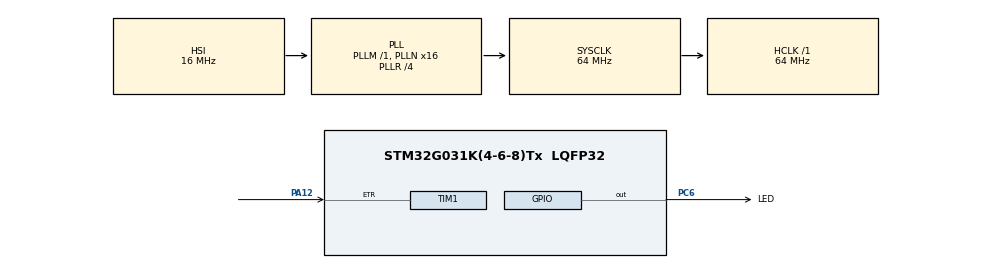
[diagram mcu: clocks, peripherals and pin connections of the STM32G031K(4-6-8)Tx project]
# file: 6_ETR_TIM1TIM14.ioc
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Mcu.Family=STM32G0
Mcu.Name=STM32G031K(4-6-8)Tx
Mcu.Package=LQFP32
NVIC.TIM17_IRQn=true\:0\:0\:false\:false\:true\:true\:true\:true
PA12\ [PA10].Signal=S_TIM1_ETR
PC6.GPIO_Label=LED
PC6.Signal=GPIO_Output
ProjectManager.HeapSize=0x200
ProjectManager.StackSize=0x400
ProjectManager.TargetToolchain=STM32CubeIDE
RCC.ADCFreq_Value=64000000
RCC.AHBFreq_Value=64000000
RCC.CortexFreq_Value=64000000
RCC.EXTERNAL_CLOCK_VALUE=12288000
RCC.HCLKFreq_Value=64000000
RCC.HSE_VALUE=8000000
RCC.HSI_VALUE=16000000
RCC.LSE_VALUE=32768
RCC.PLLN=16
RCC.PLLR=RCC_PLLR_DIV4
RCC.SYSCLKFreq_VALUE=64000000
RCC.SYSCLKSource=RCC_SYSCLKSOURCE_PLLCLK
RCC.TIM1CLockSelectionVirtual=RCC_TIM1CLKSOURCE_PLL
RCC.VCOOutputFreq_Value=256000000
SH.S_TIM1_ETR.0=TIM1_ETR,ClockSourceETR_Mode2
TIM1.ClockPrescaler=TIM_CLOCKPRESCALER_DIV8
TIM1.Prescaler=0
TIM1.TIM_MasterOutputTrigger=TIM_TRGO_RESET
TIM1.TIM_MasterSlaveMode=TIM_MASTERSLAVEMODE_DISABLE
TIM17.Channel=TIM_CHANNEL_1
TIM17.OCMode_1=TIM_OCMODE_TOGGLE
TIM17.Period=12799
TIM17.Prescaler=0
TIM17.Pulse=0
TIM17.RepetitionCounter=0
VP_TIM17_VS_ClockSourceINT.Mode=Enable_Timer
VP_TIM17_VS_no_output1.Mode=Output Compare1 No Output
VP_TIM1_VS_ClockSourceITR.Mode=TriggerSource_ITR3
VP_TIM1_VS_ControllerModeGated.Mode=Gated Mode
board=custom

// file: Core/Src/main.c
/* USER CODE BEGIN Header */
/**
  ******************************************************************************
  * @file           : main.c
  * @brief          : Main program body
  ******************************************************************************
  * @attention
  *
  * Copyright (c) 2022 STMicroelectronics.
  * All rights reserved.
  *
  * This software is licensed under terms that can be found in the LICENSE file
  * in the root directory of this software component.
  * If no LICENSE file comes with this software, it is provided AS-IS.
  *
  ******************************************************************************
  */
/* USER CODE END Header */
#include "main.h"

TIM_HandleTypeDef htim1;
TIM_HandleTypeDef htim17;

/* USER CODE BEGIN PV */
volatile uint16_t cnt_values[NB_MEASURES*2] = {0};
volatile uint32_t tim1_cnt_value1 = 0;
volatile uint32_t tim1_cnt_value2 = 0;
volatile uint32_t tim1_cnt_diff = 0;
volatile uint32_t freqs_measured[NB_MEASURES] = {0};
volatile uint32_t freq_measured = 0;
volatile uint16_t i = 0;
/* USER CODE END PV */

void SystemClock_Config(void);
static void MX_GPIO_Init(void);
static void MX_TIM1_Init(void);
static void MX_TIM17_Init(void);

int main(void)
{

  /* MCU Configuration--------------------------------------------------------*/

  /* Reset of all peripherals, Initializes the Flash interface and the Systick. */
  HAL_Init();

  /* Configure the system clock */
  SystemClock_Config();

  /* Initialize all configured peripherals */
  MX_GPIO_Init();
  MX_TIM1_Init();
  MX_TIM17_Init();
  /* USER CODE BEGIN 2 */
  HAL_TIM_Base_Start(&htim1);
  HAL_TIM_OC_Start_IT(&htim17, TIM_CHANNEL_1);

  /* USER CODE END 2 */

  /* Infinite loop */
  while (1)
  {

  }
}

void SystemClock_Config(void)
{
  RCC_OscInitTypeDef RCC_OscInitStruct = {0};
  RCC_ClkInitTypeDef RCC_ClkInitStruct = {0};

  /** Configure the main internal regulator output voltage
  */
  HAL_PWREx_ControlVoltageScaling(PWR_REGULATOR_VOLTAGE_SCALE1);

  /** Initializes the RCC Oscillators according to the specified parameters
  * in the RCC_OscInitTypeDef structure.
  */
  RCC_OscInitStruct.OscillatorType = RCC_OSCILLATORTYPE_HSI;
  RCC_OscInitStruct.HSIState = RCC_HSI_ON;
  RCC_OscInitStruct.HSIDiv = RCC_HSI_DIV1;
  RCC_OscInitStruct.HSICalibrationValue = RCC_HSICALIBRATION_DEFAULT;
  RCC_OscInitStruct.PLL.PLLState = RCC_PLL_ON;
  RCC_OscInitStruct.PLL.PLLSource = RCC_PLLSOURCE_HSI;
  RCC_OscInitStruct.PLL.PLLM = RCC_PLLM_DIV1;
  RCC_OscInitStruct.PLL.PLLN = 16;
  RCC_OscInitStruct.PLL.PLLP = RCC_PLLP_DIV2;
  RCC_OscInitStruct.PLL.PLLQ = RCC_PLLQ_DIV2;
  RCC_OscInitStruct.PLL.PLLR = RCC_PLLR_DIV4;
  if (HAL_RCC_OscConfig(&RCC_OscInitStruct) != HAL_OK)
  {
    Error_Handler();
  }

  /** Initializes the CPU, AHB and APB buses clocks
  */
  RCC_ClkInitStruct.ClockType = RCC_CLOCKTYPE_HCLK|RCC_CLOCKTYPE_SYSCLK
                              |RCC_CLOCKTYPE_PCLK1;
  RCC_ClkInitStruct.SYSCLKSource = RCC_SYSCLKSOURCE_PLLCLK;
  RCC_ClkInitStruct.AHBCLKDivider = RCC_SYSCLK_DIV1;
  RCC_ClkInitStruct.APB1CLKDivider = RCC_HCLK_DIV1;

  if (HAL_RCC_ClockConfig(&RCC_ClkInitStruct, FLASH_LATENCY_2) != HAL_OK)
  {
    Error_Handler();
  }
}

static void MX_TIM1_Init(void)
{

  TIM_ClockConfigTypeDef sClockSourceConfig = {0};
  TIM_SlaveConfigTypeDef sSlaveConfig = {0};
  TIM_MasterConfigTypeDef sMasterConfig = {0};

  htim1.Instance = TIM1;
  htim1.Init.Prescaler = 0;
  htim1.Init.CounterMode = TIM_COUNTERMODE_UP;
  htim1.Init.Period = 65535;
  htim1.Init.ClockDivision = TIM_CLOCKDIVISION_DIV1;
  htim1.Init.RepetitionCounter = 0;
  htim1.Init.AutoReloadPreload = TIM_AUTORELOAD_PRELOAD_DISABLE;
  if (HAL_TIM_Base_Init(&htim1) != HAL_OK)
  {
    Error_Handler();
  }
  sClockSourceConfig.ClockSource = TIM_CLOCKSOURCE_ETRMODE2;
  sClockSourceConfig.ClockPolarity = TIM_CLOCKPOLARITY_NONINVERTED;
  sClockSourceConfig.ClockPrescaler = TIM_CLOCKPRESCALER_DIV8;
  sClockSourceConfig.ClockFilter = 0;
  if (HAL_TIM_ConfigClockSource(&htim1, &sClockSourceConfig) != HAL_OK)
  {
    Error_Handler();
  }
  sSlaveConfig.SlaveMode = TIM_SLAVEMODE_GATED;
  sSlaveConfig.InputTrigger = TIM_TS_ITR3;
  if (HAL_TIM_SlaveConfigSynchro(&htim1, &sSlaveConfig) != HAL_OK)
  {
    Error_Handler();
  }
  sMasterConfig.MasterOutputTrigger = TIM_TRGO_RESET;
  sMasterConfig.MasterOutputTrigger2 = TIM_TRGO2_RESET;
  sMasterConfig.MasterSlaveMode = TIM_MASTERSLAVEMODE_DISABLE;
  if (HAL_TIMEx_MasterConfigSynchronization(&htim1, &sMasterConfig) != HAL_OK)
  {
    Error_Handler();
  }

}

static void MX_TIM17_Init(void)
{

  TIM_OC_InitTypeDef sConfigOC = {0};
  TIM_BreakDeadTimeConfigTypeDef sBreakDeadTimeConfig = {0};

  htim17.Instance = TIM17;
  htim17.Init.Prescaler = 0;
  htim17.Init.CounterMode = TIM_COUNTERMODE_UP;
  htim17.Init.Period = 12799;
  htim17.Init.ClockDivision = TIM_CLOCKDIVISION_DIV1;
  htim17.Init.RepetitionCounter = 0;
  htim17.Init.AutoReloadPreload = TIM_AUTORELOAD_PRELOAD_DISABLE;
  if (HAL_TIM_Base_Init(&htim17) != HAL_OK)
  {
    Error_Handler();
  }
  if (HAL_TIM_OC_Init(&htim17) != HAL_OK)
  {
    Error_Handler();
  }
  sConfigOC.OCMode = TIM_OCMODE_TOGGLE;
  sConfigOC.Pulse = 0;
  sConfigOC.OCPolarity = TIM_OCPOLARITY_HIGH;
  sConfigOC.OCNPolarity = TIM_OCNPOLARITY_HIGH;
  sConfigOC.OCFastMode = TIM_OCFAST_DISABLE;
  sConfigOC.OCIdleState = TIM_OCIDLESTATE_RESET;
  sConfigOC.OCNIdleState = TIM_OCNIDLESTATE_RESET;
  if (HAL_TIM_OC_ConfigChannel(&htim17, &sConfigOC, TIM_CHANNEL_1) != HAL_OK)
  {
    Error_Handler();
  }
  sBreakDeadTimeConfig.OffStateRunMode = TIM_OSSR_DISABLE;
  sBreakDeadTimeConfig.OffStateIDLEMode = TIM_OSSI_DISABLE;
  sBreakDeadTimeConfig.LockLevel = TIM_LOCKLEVEL_OFF;
  sBreakDeadTimeConfig.DeadTime = 0;
  sBreakDeadTimeConfig.BreakState = TIM_BREAK_DISABLE;
  sBreakDeadTimeConfig.BreakPolarity = TIM_BREAKPOLARITY_HIGH;
  sBreakDeadTimeConfig.BreakFilter = 0;
  sBreakDeadTimeConfig.AutomaticOutput = TIM_AUTOMATICOUTPUT_DISABLE;
  if (HAL_TIMEx_ConfigBreakDeadTime(&htim17, &sBreakDeadTimeConfig) != HAL_OK)
  {
    Error_Handler();
  }

}

static void MX_GPIO_Init(void)
{
  GPIO_InitTypeDef GPIO_InitStruct = {0};

  /* GPIO Ports Clock Enable */
  __HAL_RCC_GPIOC_CLK_ENABLE();
  __HAL_RCC_GPIOA_CLK_ENABLE();

  /*Configure GPIO pin Output Level */
  HAL_GPIO_WritePin(LED_GPIO_Port, LED_Pin, GPIO_PIN_RESET);

  /*Configure GPIO pin : LED_Pin */
  GPIO_InitStruct.Pin = LED_Pin;
  GPIO_InitStruct.Mode = GPIO_MODE_OUTPUT_PP;
  GPIO_InitStruct.Pull = GPIO_NOPULL;
  GPIO_InitStruct.Speed = GPIO_SPEED_FREQ_LOW;
  HAL_GPIO_Init(LED_GPIO_Port, &GPIO_InitStruct);

}

void Error_Handler(void)
{
  __disable_irq();
  while (1)
  {
  }
}
